# generated register map
File version: 1.0
Registers are 32-bit, access not given, no defined reset value unless marked. A register's access mark holds for its fields unless they carry their own. Offsets are from the block's base; lines under a group give offsets from that group; [hi:lo] are bit positions; {n}, {i} and the like mark numbered series; 'fields as' and 'values as' point back to an identical list; <NAME> marks a mode.

## Memory map
0x600A3000 ieee802154

## ieee802154
Base 0x600A3000
0x00 command
  [7:0] opcode
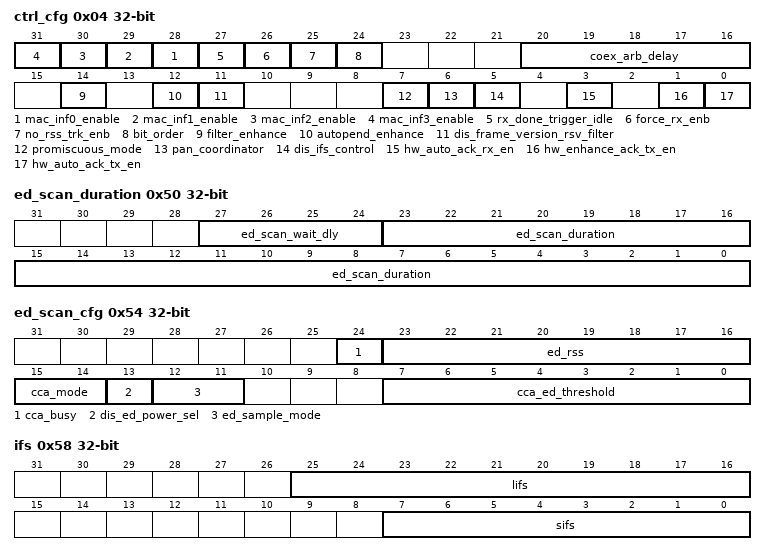
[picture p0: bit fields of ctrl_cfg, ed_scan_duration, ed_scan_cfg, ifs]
0x04 ctrl_cfg
  [n+28] mac_inf{n}_enable (n=0..3), [27] rx_done_trigger_idle, [26] force_rx_enb, [25] no_rss_trk_enb, [24] bit_order, [20:16] coex_arb_delay, [14] filter_enhance, [12] autopend_enhance, [11] dis_frame_version_rsv_filter, [7] promiscuous_mode, [6] pan_coordinator, [5] dis_ifs_control, [3] hw_auto_ack_rx_en, [1] hw_enhance_ack_tx_en, [0] hw_auto_ack_tx_en
{0x8+0x10*i} inf{i}_short_addr (i=0..3)
  [15:0] mac_inf{i}_short_addr
{0xC+0x10*i} inf{i}_pan_id (i=0..3)
  [15:0] mac_inf{i}_pan_id
{0x10+0x10*i} inf{i}_extend_addr0 (i=0..3)
  [31:0] mac_inf{i}_extend_addr0
{0x14+0x10*i} inf{i}_extend_addr1 (i=0..3)
  [31:0] mac_inf{i}_extend_addr1
0x48 channel
  [6:0] hop
0x4C tx_power
  [4:0] tx_power
0x50 ed_scan_duration
  [27:24] ed_scan_wait_dly, [23:0] ed_scan_duration
0x54 ed_scan_cfg
  [24] cca_busy, [23:16] ed_rss, [15:14] cca_mode, [13] dis_ed_power_sel, [12:11] ed_sample_mode, [7:0] cca_ed_threshold
0x58 ifs
  [25:16] lifs, [7:0] sifs
0x5C ack_timeout
  [15:0] ack_timeout
0x60 event_en
  [12:0] event_en
0x64 event_status
  [12:0] event_status
0x68 rx_abort_intr_ctrl
  [30:0] rx_abort_intr_ctrl
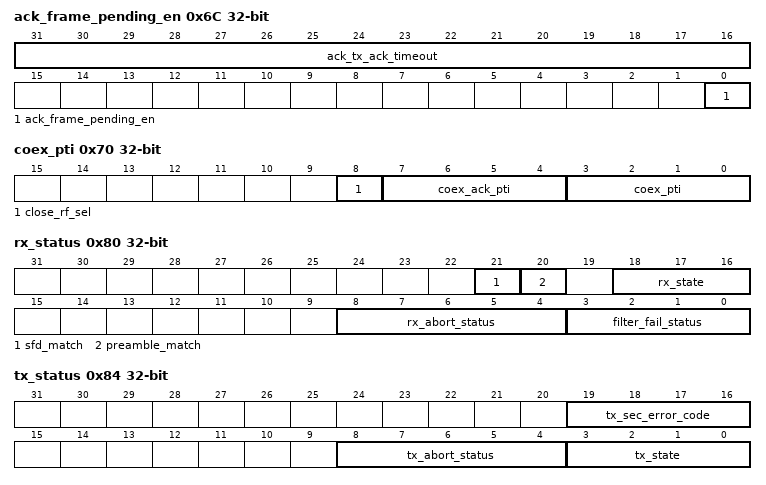
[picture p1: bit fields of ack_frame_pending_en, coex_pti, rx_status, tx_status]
0x6C ack_frame_pending_en
  [31:16] ack_tx_ack_timeout, [0] ack_frame_pending_en
0x70 coex_pti
  [8] close_rf_sel, [7:4] coex_ack_pti, [3:0] coex_pti
0x74 core_dummy_data
0x78 tx_abort_interrupt_control
  [30:0] tx_abort_interrupt_control
0x7C enhance_ack_cfg
  [31:0] tx_enh_ack_generate_done_notify
0x80 rx_status
  [21] sfd_match, [20] preamble_match, [18:16] rx_state, [8:4] rx_abort_status, [3:0] filter_fail_status
0x84 tx_status
  [19:16] tx_sec_error_code, [8:4] tx_abort_status, [3:0] tx_state
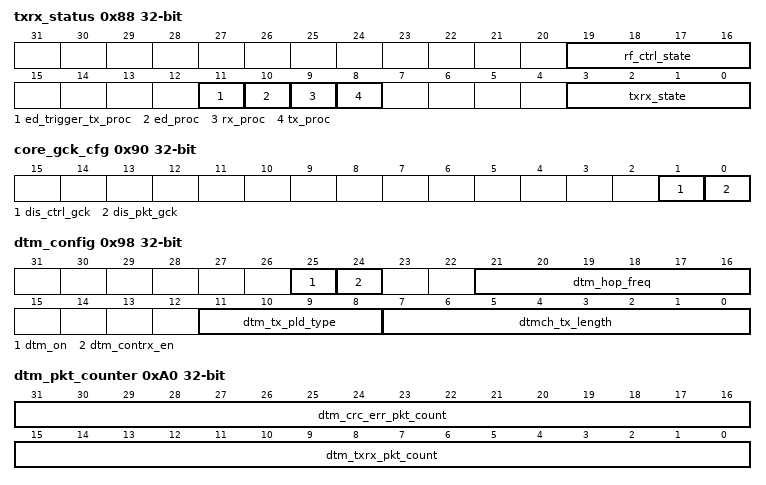
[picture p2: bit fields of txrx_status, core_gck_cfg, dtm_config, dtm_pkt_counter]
0x88 txrx_status
  [19:16] rf_ctrl_state, [11] ed_trigger_tx_proc, [10] ed_proc, [9] rx_proc, [8] tx_proc, [3:0] txrx_state
0x8C tx_ccm_schedule_status
  [30:0] tx_ccm_schedule_status
0x90 core_gck_cfg
  [1] dis_ctrl_gck, [0] dis_pkt_gck
0x94 test_control
  [0] wrong_crc
0x98 dtm_config
  [25] dtm_on, [24] dtm_contrx_en, [21:16] dtm_hop_freq, [11:8] dtm_tx_pld_type, [7:0] dtmch_tx_length
0x9C dtm_tx_pkt_config
  [15:0] dtm_tx_pkt_threshold
0xA0 dtm_pkt_counter
  [31:16] dtm_crc_err_pkt_count, [15:0] dtm_txrx_pkt_count
0xA4 rx_length
  [6:0] rx_length
0xA8 time0_threshold
  [31:0] timer0_threshold
0xAC time0_value
  [31:0] timer0_value
0xB0 time1_threshold
  [31:0] timer1_threshold
0xB4 time1_value
  [31:0] timer1_value
0xB8 clk_counter_match_val
  [15:0] clk_count_match_val
0xBC clk_counter
  [15:0] clk_625us_cnt
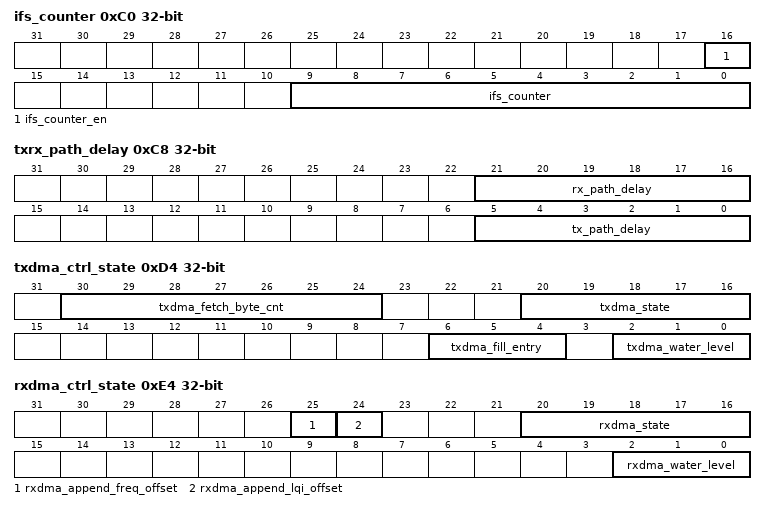
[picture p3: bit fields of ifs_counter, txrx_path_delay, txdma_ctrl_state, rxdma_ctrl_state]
0xC0 ifs_counter
  [16] ifs_counter_en, [9:0] ifs_counter
0xC4 sfd_wait_symbol
  [3:0] sfd_wait_symbol_num
0xC8 txrx_path_delay
  [21:16] rx_path_delay, [5:0] tx_path_delay
0xCC bb_clk
  [4:0] bb_clk_freq_minus_1
0xD0 txdma_addr
0xD4 txdma_ctrl_state
  [30:24] txdma_fetch_byte_cnt, [20:16] txdma_state, [6:4] txdma_fill_entry, [2:0] txdma_water_level
0xD8 txdma_err
  [3:0] txdma_err
0xE0 rxdma_addr
0xE4 rxdma_ctrl_state
  [25] rxdma_append_freq_offset, [24] rxdma_append_lqi_offset, [20:16] rxdma_state, [2:0] rxdma_water_level
0xE8 rxdma_err
  [3:0] rxdma_err
0xF0 dma_gck_cfg
  [0] dma_gck_cfg
0xF4 dma_dummy
  [31:0] dma_dummy_data
0x100 paon_delay
  [9:0] paon_delay
0x104 txon_delay
  [9:0] txon_delay
0x108 txen_stop_delay
  [5:0] txen_stop_dly
0x10C txoff_delay
  [5:0] txoff_delay
0x110 rxon_delay
  [10:0] rxon_delay
0x114 txrx_switch_delay
  [9:0] txrx_switch_delay
0x118 cont_rx_delay
  [5:0] cont_rx_delay
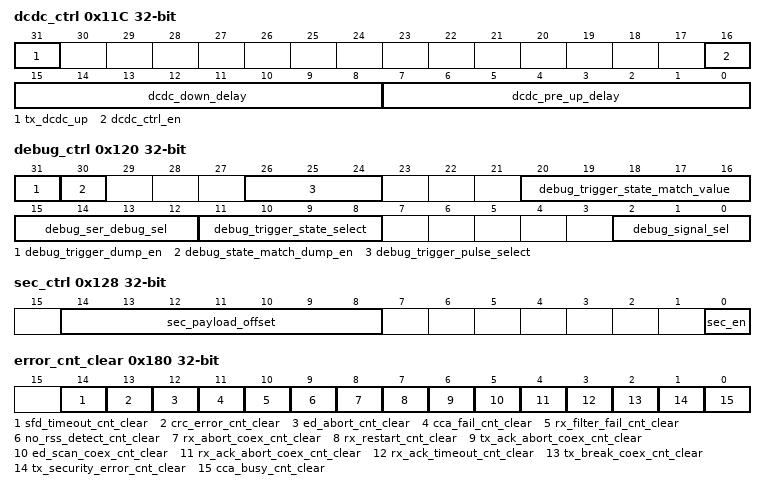
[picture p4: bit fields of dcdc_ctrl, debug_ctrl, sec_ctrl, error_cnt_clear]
0x11C dcdc_ctrl
  [31] tx_dcdc_up, [16] dcdc_ctrl_en, [15:8] dcdc_down_delay, [7:0] dcdc_pre_up_delay
0x120 debug_ctrl
  [31] debug_trigger_dump_en, [30] debug_state_match_dump_en, [26:24] debug_trigger_pulse_select, [20:16] debug_trigger_state_match_value, [15:12] debug_ser_debug_sel, [11:8] debug_trigger_state_select, [2:0] debug_signal_sel
0x128 sec_ctrl
  [14:8] sec_payload_offset, [0] sec_en
0x12C sec_extend_address0
0x130 sec_extend_address1
{0x134+4i} sec_key{i} (i=0..3)
0x144 sfd_timeout_cnt
  [15:0] sfd_timeout_cnt
0x148 crc_error_cnt
  [15:0] crc_error_cnt
0x14C ed_abort_cnt
  [15:0] ed_abort_cnt
0x150 cca_fail_cnt
  [15:0] cca_fail_cnt
0x154 rx_filter_fail_cnt
  [15:0] rx_filter_fail_cnt
0x158 no_rss_detect_cnt
  [15:0] no_rss_detect_cnt
0x15C rx_abort_coex_cnt
  [15:0] rx_abort_coex_cnt
0x160 rx_restart_cnt
  [15:0] rx_restart_cnt
0x164 tx_ack_abort_coex_cnt
  [15:0] tx_ack_abort_coex_cnt
0x168 ed_scan_coex_cnt
  [15:0] ed_scan_coex_cnt
0x16C rx_ack_abort_coex_cnt
  [15:0] rx_ack_abort_coex_cnt
0x170 rx_ack_timeout_cnt
  [15:0] rx_ack_timeout_cnt
0x174 tx_break_coex_cnt
  [15:0] tx_break_coex_cnt
0x178 tx_security_error_cnt
  [15:0] tx_security_error_cnt
0x17C cca_busy_cnt
  [15:0] cca_busy_cnt
0x180 error_cnt_clear
  [14] sfd_timeout_cnt_clear, [13] crc_error_cnt_clear, [12] ed_abort_cnt_clear, [11] cca_fail_cnt_clear, [10] rx_filter_fail_cnt_clear, [9] no_rss_detect_cnt_clear, [8] rx_abort_coex_cnt_clear, [7] rx_restart_cnt_clear, [6] tx_ack_abort_coex_cnt_clear, [5] ed_scan_coex_cnt_clear, [4] rx_ack_abort_coex_cnt_clear, [3] rx_ack_timeout_cnt_clear, [2] tx_break_coex_cnt_clear, [1] tx_security_error_cnt_clear, [0] cca_busy_cnt_clear
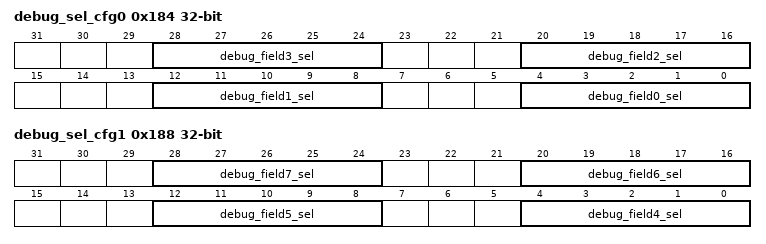
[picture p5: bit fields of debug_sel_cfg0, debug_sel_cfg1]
0x184 debug_sel_cfg0
  [8n+4:8n] debug_field{n}_sel (n=0..3)
0x184 mac_date
0x188 debug_sel_cfg1
  [8n-28:8n-32] debug_field{n}_sel (n=4..7)
0x18C mac_date
